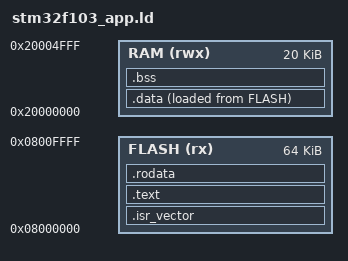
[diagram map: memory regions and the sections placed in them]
MEMORY
{
    FLASH (rx)  : ORIGIN = 0x08000000, LENGTH = 64K
    RAM   (rwx) : ORIGIN = 0x20000000, LENGTH = 20K
}

_estack = ORIGIN(RAM) + LENGTH(RAM);

SECTIONS
{
    .isr_vector : {
        . = ALIGN(4);
        KEEP(*(.isr_vector))
        . = ALIGN(4);
    } > FLASH

    .text : {
        . = ALIGN(4);
        *(.text)
        *(.text*)
        *(.glue_7)
        *(.glue_7t)
        *(.eh_frame)
        . = ALIGN(4);
    } > FLASH

    .rodata : {
        . = ALIGN(4);
        *(.rodata)
        *(.rodata*)
        . = ALIGN(4);
    } > FLASH

    _sidata = LOADADDR(.data);

    .data : {
        . = ALIGN(4);
        _sdata = .;
        *(.data)
        *(.data*)
        . = ALIGN(4);
        _edata = .;
    } > RAM AT> FLASH

    .bss : {
        . = ALIGN(4);
        _sbss = .;
        *(.bss)
        *(.bss*)
        *(COMMON)
        . = ALIGN(4);
        _ebss = .;
    } > RAM

    . = ALIGN(4);
    _heap_start = .;
    _heap_end = ORIGIN(RAM) + LENGTH(RAM);
}
